VERSION ""

NS_ :

BS_:

BU_:

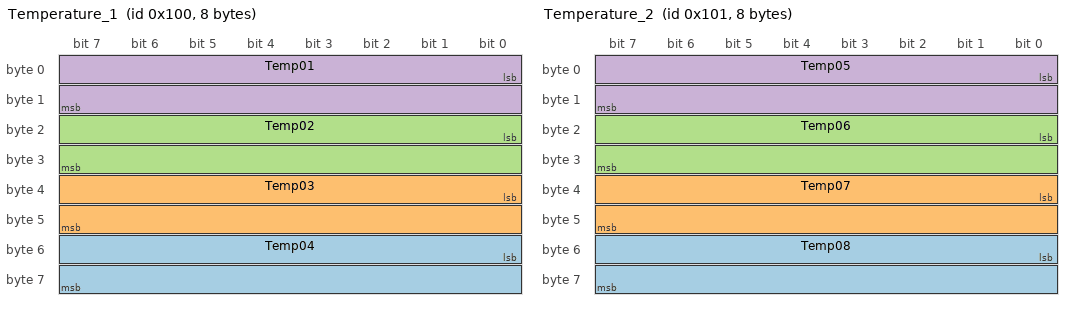
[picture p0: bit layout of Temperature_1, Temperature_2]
BO_ 256 Temperature_1: 8 Vector__XXX
 SG_ Temp04 : 48|16@1- (0.1,0) [0|0] "degC" Vector__XXX
 SG_ Temp03 : 32|16@1- (0.1,0) [0|0] "degC" Vector__XXX
 SG_ Temp02 : 16|16@1- (0.1,0) [0|0] "degC" Vector__XXX
 SG_ Temp01 : 0|16@1- (0.1,0) [0|0] "degC" Vector__XXX

BO_ 257 Temperature_2: 8 Vector__XXX
 SG_ Temp08 : 48|16@1- (0.1,0) [0|0] "degC" Vector__XXX
 SG_ Temp07 : 32|16@1- (0.1,0) [0|0] "degC" Vector__XXX
 SG_ Temp06 : 16|16@1- (0.1,0) [0|0] "degC" Vector__XXX
 SG_ Temp05 : 0|16@1- (0.1,0) [0|0] "degC" Vector__XXX

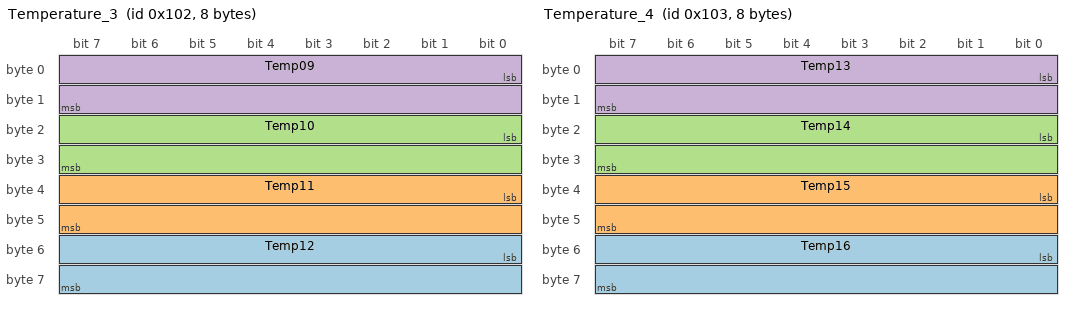
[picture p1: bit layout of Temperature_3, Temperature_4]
BO_ 258 Temperature_3: 8 Vector__XXX
 SG_ Temp12 : 48|16@1- (0.1,0) [0|0] "degC" Vector__XXX
 SG_ Temp11 : 32|16@1- (0.1,0) [0|0] "degC" Vector__XXX
 SG_ Temp10 : 16|16@1- (0.1,0) [0|0] "degC" Vector__XXX
 SG_ Temp09 : 0|16@1- (0.1,0) [0|0] "degC" Vector__XXX

BO_ 259 Temperature_4: 8 Vector__XXX
 SG_ Temp16 : 48|16@1- (0.1,0) [0|0] "degC" Vector__XXX
 SG_ Temp15 : 32|16@1- (0.1,0) [0|0] "degC" Vector__XXX
 SG_ Temp14 : 16|16@1- (0.1,0) [0|0] "degC" Vector__XXX
 SG_ Temp13 : 0|16@1- (0.1,0) [0|0] "degC" Vector__XXX

BA_DEF_  "BusType" STRING ;
BA_DEF_DEF_  "BusType" "CAN";
